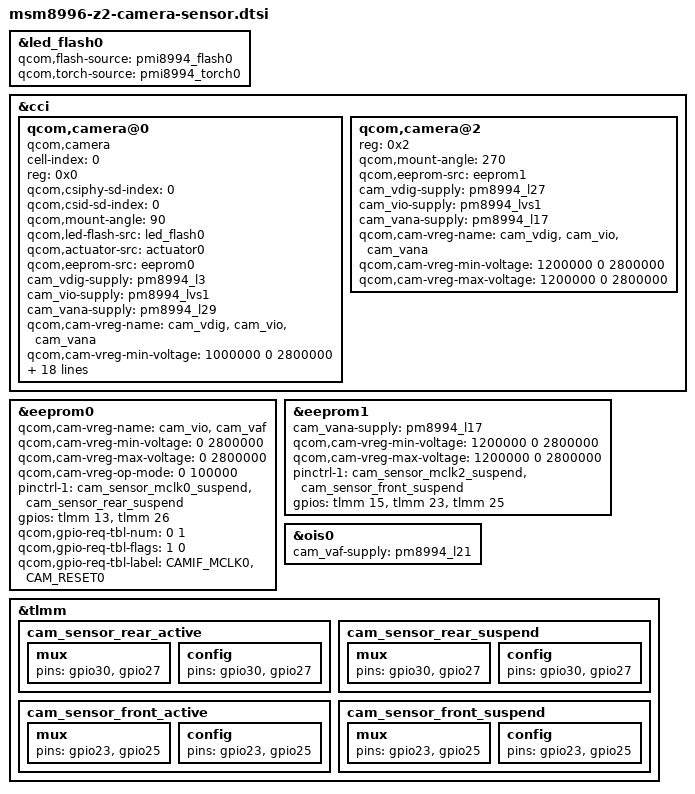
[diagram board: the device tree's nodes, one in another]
&led_flash0 {
	qcom,flash-source = <&pmi8994_flash0>;
	qcom,torch-source = <&pmi8994_torch0>;
};

&cci {
	qcom,camera@0 {
		cell-index = <0>;
		compatible = "qcom,camera";
		reg = <0x0>;
		qcom,csiphy-sd-index = <0>;
		qcom,csid-sd-index = <0>;
		qcom,mount-angle = <90>;
		qcom,led-flash-src = <&led_flash0>;
		qcom,actuator-src = <&actuator0>;
		qcom,eeprom-src = <&eeprom0>;
		cam_vdig-supply = <&pm8994_l3>;
		cam_vio-supply = <&pm8994_lvs1>;
		cam_vana-supply = <&pm8994_l29>;
		qcom,cam-vreg-name = "cam_vdig", "cam_vio", "cam_vana";
		qcom,cam-vreg-min-voltage = <1000000 0 2800000>;
		qcom,cam-vreg-max-voltage = <1000000 0 2800000>;
		qcom,cam-vreg-op-mode = <105000 0 100000>;
		qcom,gpio-no-mux = <0>;
		pinctrl-names = "cam_default", "cam_suspend";
		pinctrl-0 = <&cam_sensor_mclk0_active &cam_sensor_rear_active>;
		pinctrl-1 = <&cam_sensor_mclk0_suspend &cam_sensor_rear_suspend>;
		gpios = <&tlmm 13 0>,
			<&tlmm 26 0>;
		qcom,gpio-reset = <1>;

		qcom,gpio-req-tbl-num = <0 1>;
		qcom,gpio-req-tbl-flags = <1 0>;
		qcom,gpio-req-tbl-label = "CAMIF_MCLK0", "CAM_RESET0";
		qcom,sensor-position = <0>;
		qcom,sensor-mode = <0>;
		qcom,cci-master = <0>;
		status = "ok";
		clocks = <&clock_mmss clk_mclk0_clk_src>,
				<&clock_mmss clk_camss_mclk0_clk>;
		clock-names = "cam_src_clk", "cam_clk";
	};
	
	qcom,camera@2 {
		reg = <0x2>;
		qcom,mount-angle = <270>;
		qcom,eeprom-src = <&eeprom1>;
		cam_vdig-supply = <&pm8994_l27>;
		cam_vio-supply = <&pm8994_lvs1>;
		cam_vana-supply = <&pm8994_l17>;
		qcom,cam-vreg-name = "cam_vdig", "cam_vio", "cam_vana";
		qcom,cam-vreg-min-voltage = <1200000 0 2800000>;
		qcom,cam-vreg-max-voltage = <1200000 0 2800000>;
	};
};

&eeprom0 {
	/delete-property/ cam_vdig-supply;
	/delete-property/ cam_vana-supply;
	qcom,cam-vreg-name = "cam_vio", "cam_vaf";
	qcom,cam-vreg-min-voltage = <0 2800000>;
	qcom,cam-vreg-max-voltage = <0 2800000>;
	qcom,cam-vreg-op-mode = <0 100000>;
	pinctrl-1 = <&cam_sensor_mclk0_suspend &cam_sensor_rear_suspend>;
	gpios = <&tlmm 13 0>, <&tlmm 26 0>;
	/delete-property/ qcom,gpio-standby;
	qcom,gpio-req-tbl-num = <0 1>;
	qcom,gpio-req-tbl-flags = <1 0>;
	qcom,gpio-req-tbl-label = "CAMIF_MCLK0", "CAM_RESET0";
};

&eeprom1 {
	cam_vana-supply = <&pm8994_l17>;
	qcom,cam-vreg-min-voltage = <1200000 0 2800000>;
	qcom,cam-vreg-max-voltage = <1200000 0 2800000>;
	pinctrl-1 = <&cam_sensor_mclk2_suspend &cam_sensor_front_suspend>;
	gpios = <&tlmm 15 0>, <&tlmm 23 0>, <&tlmm 25 0>;
};

&ois0 {
	cam_vaf-supply = <&pm8994_l21>;
};
&tlmm {
	cam_sensor_rear_active: cam_sensor_rear_active {
		mux {
			pins = "gpio30", "gpio27";
		};
		config {
			pins = "gpio30", "gpio27";
		};
	};

	cam_sensor_rear_suspend: cam_sensor_rear_suspend {
		mux {
			pins = "gpio30", "gpio27";
		};
		config {
			pins = "gpio30", "gpio27";
		};
	};

	cam_sensor_front_active: cam_sensor_front_active {
		mux {
			pins = "gpio23","gpio25";
		};
		config {
			pins = "gpio23","gpio25";
		};
	};

	cam_sensor_front_suspend: cam_sensor_front_suspend {
		mux {
			pins = "gpio23","gpio25";
		};
		config {
			pins = "gpio23","gpio25";
		};
	};
};


